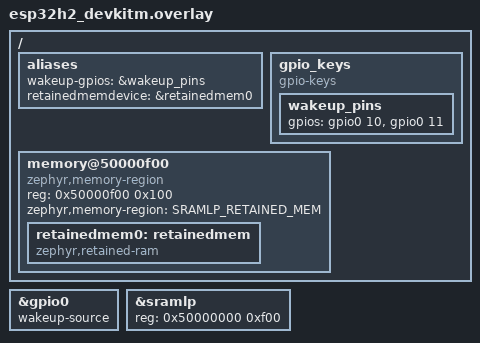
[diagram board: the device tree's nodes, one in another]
/*
 * Copyright (c) 2025-2026 Espressif Systems (Shanghai) Co., Ltd.
 *
 * SPDX-License-Identifier: Apache-2.0
 */

/ {
	aliases {
		wakeup-gpios = &wakeup_pins;
		retainedmemdevice = &retainedmem0;
	};

	gpio_keys {
		compatible = "gpio-keys";

		wakeup_pins: wakeup_pins {
			gpios = <&gpio0 10 (GPIO_PULL_DOWN | GPIO_ACTIVE_HIGH | GPIO_INT_WAKEUP)>,
				<&gpio0 11 (GPIO_PULL_DOWN | GPIO_ACTIVE_HIGH | GPIO_INT_WAKEUP)>;
		};
	};

	memory@50000f00 {
		compatible = "zephyr,memory-region", "mmio-sram";
		reg = <0x50000f00 0x100>;
		zephyr,memory-region = "SRAMLP_RETAINED_MEM";
		status = "okay";

		retainedmem0: retainedmem {
			compatible = "zephyr,retained-ram";
			status = "okay";
		};
	};
};

&gpio0 {
	/* Configure device as wakeup source */
	wakeup-source;
};

&sramlp {
	/* Shrink sramlp size to avoid overlap with retained memory region:
	 * 4KB - 256 = 0xf00
	 */
	reg = <0x50000000 0xf00>;
};
